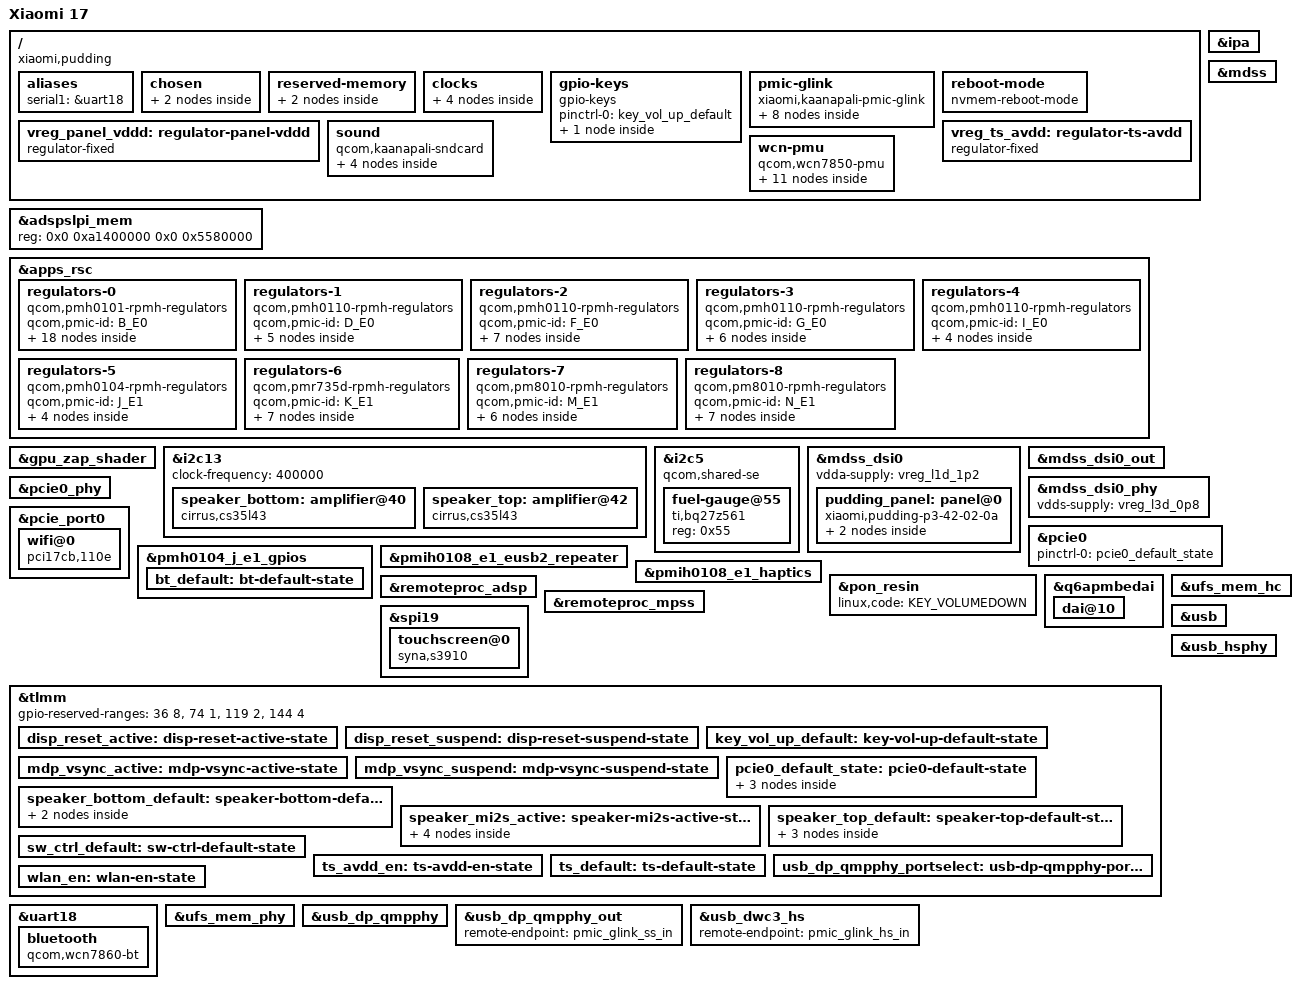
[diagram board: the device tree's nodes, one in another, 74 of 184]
// SPDX-License-Identifier: BSD-3-Clause
/*
 * Xiaomi 17 (pudding), based on kaanapali-mtp.dts
 *
 * Copyright (c) Qualcomm Technologies, Inc. and/or its subsidiaries.
 */

/dts-v1/;

#include <dt-bindings/gpio/gpio.h>
#include <dt-bindings/input/linux-event-codes.h>
#include <dt-bindings/regulator/qcom,rpmh-regulator.h>
/*
 * CPU throttle temperature for kaanapali-cpu-cooling.dtsi: 105 °C is the
 * thermal HAL trip of the cpu-* zones in this phone's stock device tree.
 */
#define KAANAPALI_CPU_PASSIVE_MC 105000
#include "kaanapali.dtsi"

#include "pm8010-kaanapali.dtsi"     /* SPMI1: SID-12/13   */
#include "pmd8028-kaanapali.dtsi"    /* SPMI1: SID-4       */
#include "pmh0101.dtsi"              /* SPMI0: SID-1       */
#include "pmh0104-kaanapali.dtsi"    /* SPMI1: SID-9       */
#include "pmh0110-kaanapali.dtsi"    /* SPMI0: SID-3/5/6/8 */
#include "pmih0108-kaanapali.dtsi"   /* SPMI1: SID-7       */
#include "pmk8850.dtsi"              /* SPMI0: SID-0       */
#include "pmr735d-kaanapali.dtsi"    /* SPMI1: SID-10      */

/ {
	model = "Xiaomi 17";
	compatible = "xiaomi,pudding", "qcom,kaanapali";
	chassis-type = "handset";

	aliases {
		serial1 = &uart18;
	};

	chosen {
		#address-cells = <2>;
		#size-cells = <2>;
		ranges;

		/*
		 * Reboot a minute after a panic or a soft lockup, leaving the
		 * message on screen: the phone has no serial console and should
		 * not need a key reset. The bootloader splash shows the console
		 * until the display driver takes over: keep its clocks and power
		 * domains on. The bootloader always loads init_boot's ramdisk,
		 * and Android's /init may share it: the rescue starts from its
		 * own directory. The GPU is a DRM device of its own, apart from
		 * the display.
		 */
		bootargs = "rdinit=/pudding-rescue/load console=tty0 panic=60 softlockup_panic=1 loglevel=7 log_buf_len=2M bootconfig clk_ignore_unused pd_ignore_unused msm.separate_gpu_kms=1";

		/*
		 * The ABL boots vendor_boot's Canoe tree with the dtbo overlay
		 * for board-id 8 and Xiaomi board 2, whose root model names this
		 * phone. The bootloader ramdisk carries the rescue and boot
		 * userspace.
		 */
		fdt-handoff {
			stock-compatible = "qcom,canoe";
			stock-model = "Qualcomm Technologies, Inc. Pudding based on SM8850";
			keep-initrd;
		};

		/* Bootloader splash, left running by the ABL (1220x2656 DSC panel) */
		framebuffer: framebuffer@fc800000 {
			compatible = "simple-framebuffer";
			reg = <0x0 0xfc800000 0x0 (1220 * 2656 * 4)>;
			width = <1220>;
			height = <2656>;
			stride = <(1220 * 4)>;
			format = "a8r8g8b8";
			/* Keep the splash scanout fed after interconnect sync_state. */
			interconnects = <&mmss_noc MASTER_MDP QCOM_ICC_TAG_ALWAYS
					 &mc_virt SLAVE_EBI1 QCOM_ICC_TAG_ALWAYS>;
			clocks = <&gcc GCC_DISP_HF_AXI_CLK>;
		};
	};

	reserved-memory {
		#address-cells = <2>;
		#size-cells = <2>;
		ranges;

		cont_splash_mem: cont-splash@fc800000 {
			reg = <0x0 0xfc800000 0x0 0x2b00000>;
			no-map;
		};

		/*
		 * Same layout as the stock tree, so Android shows our log in
		 * /sys/fs/pstore. Write-combine (mem-type 0): a cached mapping
		 * would lose the log in the CPU caches on a hard reset.
		 */
		ramoops@ff400000 {
			compatible = "ramoops";
			reg = <0x0 0xff400000 0x0 0x200000>;
			console-size = <0x100000>;
			pmsg-size = <0x100000>;
			mem-type = <0>;
		};
	};

	clocks {
		xo_board: xo-board {
			compatible = "fixed-clock";
			clock-frequency = <76800000>;
			#clock-cells = <0>;
		};

		sleep_clk: sleep-clk {
			compatible = "fixed-clock";
			clock-frequency = <32764>;
			#clock-cells = <0>;
		};

		bi_tcxo_div2: bi-tcxo-div2-clk {
			compatible = "fixed-factor-clock";
			#clock-cells = <0>;

			clocks = <&rpmhcc RPMH_CXO_CLK>;
			clock-mult = <1>;
			clock-div = <2>;
		};

		bi_tcxo_ao_div2: bi-tcxo-ao-div2-clk {
			compatible = "fixed-factor-clock";
			#clock-cells = <0>;

			clocks = <&rpmhcc RPMH_CXO_CLK_A>;
			clock-mult = <1>;
			clock-div = <2>;
		};
	};

	gpio-keys {
		compatible = "gpio-keys";

		pinctrl-0 = <&key_vol_up_default>;
		pinctrl-names = "default";

		key-volume-up {
			label = "Volume Up";
			linux,code = <KEY_VOLUMEUP>;
			gpios = <&tlmm 101 GPIO_ACTIVE_LOW>;
			debounce-interval = <15>;
			linux,can-disable;
			wakeup-source;
		};
	};

	pmic-glink {
		compatible = "xiaomi,kaanapali-pmic-glink", "qcom,kaanapali-pmic-glink",
			     "qcom,pmic-glink";
		#address-cells = <1>;
		#size-cells = <0>;

		connector@0 {
			compatible = "usb-c-connector";
			reg = <0>;

			power-role = "dual";
			data-role = "dual";

			ports {
				#address-cells = <1>;
				#size-cells = <0>;

				port@0 {
					reg = <0>;

					pmic_glink_hs_in: endpoint {
						remote-endpoint = <&usb_dwc3_hs>;
					};
				};

				port@1 {
					reg = <1>;

					pmic_glink_ss_in: endpoint {
						remote-endpoint = <&usb_dp_qmpphy_out>;
					};
				};

				port@2 {
					reg = <2>;

					pmic_glink_sbu: endpoint {
					};
				};
			};
		};
	};

	/* The stock kernel leaves the same values in this cell. */
	reboot-mode {
		compatible = "nvmem-reboot-mode";
		nvmem-cells = <&reboot_reason>;
		nvmem-cell-names = "reboot-mode";
		mode-recovery = <0x01>;
		mode-bootloader = <0x02>;
	};

	/* Panel core supply, a GPIO-switched rail the bootloader leaves on */
	vreg_panel_vddd: regulator-panel-vddd {
		compatible = "regulator-fixed";
		regulator-name = "vreg_panel_vddd";
		regulator-min-microvolt = <1060000>;
		regulator-max-microvolt = <1060000>;
		gpio = <&tlmm 90 GPIO_ACTIVE_HIGH>;
		enable-active-high;
		regulator-boot-on;
	};

	/* Touch analog supply, a GPIO-switched rail with no stock voltage */
	vreg_ts_avdd: regulator-ts-avdd {
		compatible = "regulator-fixed";
		regulator-name = "vreg_ts_avdd";
		gpio = <&tlmm 117 GPIO_ACTIVE_HIGH>;
		enable-active-high;

		pinctrl-0 = <&ts_avdd_en>;
		pinctrl-names = "default";
	};

	sound {
		compatible = "qcom,kaanapali-sndcard", "qcom,sm8450-sndcard";
		model = "Xiaomi-17";

		pinctrl-0 = <&speaker_mi2s_active>;
		pinctrl-names = "default";

		speaker-playback-dai-link {
			link-name = "Speaker Playback";

			codec {
				sound-dai = <&speaker_bottom>, <&speaker_top>;
			};

			cpu {
				sound-dai = <&q6apmbedai PRIMARY_MI2S_RX>;
			};

			platform {
				sound-dai = <&q6apm>;
			};
		};
	};

	/*
	 * The Wi-Fi/BT combo is Qualcomm's "peach" (PCI 17cb:110e), wired as
	 * on the RedMagic 11 Pro: same enable GPIOs, supplies and RF clock
	 * (stock qcom,cnss-peach).
	 */
	wcn-pmu {
		compatible = "qcom,wcn7850-pmu";

		pinctrl-0 = <&bt_default>, <&sw_ctrl_default>, <&wlan_en>;
		pinctrl-names = "default";

		bt-enable-gpios = <&pmh0104_j_e1_gpios 5 GPIO_ACTIVE_HIGH>;
		wlan-enable-gpios = <&tlmm 16 GPIO_ACTIVE_HIGH>;

		vdd-supply = <&vreg_s2j_0p8>;
		vddio-supply = <&vreg_l2g_1p8>;
		vddio1p2-supply = <&vreg_l3g_1p2>;
		vddaon-supply = <&vreg_s7g_0p9>;
		vdddig-supply = <&vreg_s1j_0p8>;
		vddrfa1p2-supply = <&vreg_s7f_1p2>;
		vddrfa1p8-supply = <&vreg_s8f_1p8>;

		clocks = <&rpmhcc RPMH_RF_CLK1>;

		regulators {
			vreg_pmu_rfa_cmn: ldo0 {
				regulator-name = "vreg_pmu_rfa_cmn";
			};

			vreg_pmu_aon_0p59: ldo1 {
				regulator-name = "vreg_pmu_aon_0p59";
			};

			vreg_pmu_wlcx_0p8: ldo2 {
				regulator-name = "vreg_pmu_wlcx_0p8";
			};

			vreg_pmu_wlmx_0p85: ldo3 {
				regulator-name = "vreg_pmu_wlmx_0p85";
			};

			vreg_pmu_btcmx_0p85: ldo4 {
				regulator-name = "vreg_pmu_btcmx_0p85";
			};

			vreg_pmu_rfa_0p8: ldo5 {
				regulator-name = "vreg_pmu_rfa_0p8";
			};

			vreg_pmu_rfa_1p2: ldo6 {
				regulator-name = "vreg_pmu_rfa_1p2";
			};

			vreg_pmu_rfa_1p8: ldo7 {
				regulator-name = "vreg_pmu_rfa_1p8";
			};

			vreg_pmu_pcie_0p9: ldo8 {
				regulator-name = "vreg_pmu_pcie_0p9";
			};

			vreg_pmu_pcie_1p8: ldo9 {
				regulator-name = "vreg_pmu_pcie_1p8";
			};
		};
	};
};

/* Xiaomi's ADSP firmware spans 85.5 MiB, as the stock carve-out does */
&adspslpi_mem {
	reg = <0x0 0xa1400000 0x0 0x5580000>;
};

&apps_rsc {
	regulators-0 {
		compatible = "qcom,pmh0101-rpmh-regulators";
		qcom,pmic-id = "B_E0";

		/* Stock 3.4 V, between two of the BOB's 32 mV steps. */
		vreg_bob1: bob1 {
			regulator-name = "vreg_bob1";
			regulator-min-microvolt = <3416000>;
			regulator-max-microvolt = <3416000>;
			regulator-initial-mode = <RPMH_REGULATOR_MODE_HPM>;
		};

		vreg_bob2: bob2 {
			regulator-name = "vreg_bob2";
			regulator-min-microvolt = <2704000>;
			regulator-max-microvolt = <3296000>;
			regulator-initial-mode = <RPMH_REGULATOR_MODE_HPM>;
		};

		vreg_l1b_1p8: ldo1 {
			regulator-name = "vreg_l1b_1p8";
			regulator-min-microvolt = <1800000>;
			regulator-max-microvolt = <1800000>;
			regulator-initial-mode = <RPMH_REGULATOR_MODE_AUTO>;
			regulator-allow-set-load;
			regulator-allowed-modes = <RPMH_REGULATOR_MODE_LPM
						   RPMH_REGULATOR_MODE_AUTO>;
		};

		vreg_l2b_3p3: ldo2 {
			regulator-name = "vreg_l2b_3p3";
			regulator-min-microvolt = <3304000>;
			regulator-max-microvolt = <3304000>;
			regulator-initial-mode = <RPMH_REGULATOR_MODE_AUTO>;
			regulator-allow-set-load;
			regulator-allowed-modes = <RPMH_REGULATOR_MODE_LPM
						   RPMH_REGULATOR_MODE_AUTO>;
		};

		vreg_l4b_1p8: ldo4 {
			regulator-name = "vreg_l4b_1p8";
			regulator-min-microvolt = <1800000>;
			regulator-max-microvolt = <1800000>;
			regulator-initial-mode = <RPMH_REGULATOR_MODE_AUTO>;
			regulator-allow-set-load;
			regulator-allowed-modes = <RPMH_REGULATOR_MODE_LPM
						   RPMH_REGULATOR_MODE_AUTO>;
		};

		vreg_l5b_3p1: ldo5 {
			regulator-name = "vreg_l5b_3p1";
			regulator-min-microvolt = <3100000>;
			regulator-max-microvolt = <3148000>;
			regulator-initial-mode = <RPMH_REGULATOR_MODE_AUTO>;
			regulator-allow-set-load;
			regulator-allowed-modes = <RPMH_REGULATOR_MODE_LPM
						   RPMH_REGULATOR_MODE_AUTO>;
		};

		vreg_l6b_1p8: ldo6 {
			regulator-name = "vreg_l6b_1p8";
			regulator-min-microvolt = <1800000>;
			regulator-max-microvolt = <3008000>;
			regulator-initial-mode = <RPMH_REGULATOR_MODE_AUTO>;
			regulator-allow-set-load;
			regulator-allowed-modes = <RPMH_REGULATOR_MODE_LPM
						   RPMH_REGULATOR_MODE_AUTO>;
		};

		vreg_l7b_1p8: ldo7 {
			regulator-name = "vreg_l7b_1p8";
			regulator-min-microvolt = <1800000>;
			regulator-max-microvolt = <3008000>;
			regulator-initial-mode = <RPMH_REGULATOR_MODE_AUTO>;
			regulator-allow-set-load;
			regulator-allowed-modes = <RPMH_REGULATOR_MODE_LPM
						   RPMH_REGULATOR_MODE_AUTO>;
		};

		vreg_l8b_1p8: ldo8 {
			regulator-name = "vreg_l8b_1p8";
			regulator-min-microvolt = <1800000>;
			regulator-max-microvolt = <3008000>;
			regulator-initial-mode = <RPMH_REGULATOR_MODE_AUTO>;
			regulator-allow-set-load;
			regulator-allowed-modes = <RPMH_REGULATOR_MODE_LPM
						   RPMH_REGULATOR_MODE_AUTO>;
		};

		/* Stock 3.3 V, above this LDO's top step. */
		vreg_l9b_3p3: ldo9 {
			regulator-name = "vreg_l9b_3p3";
			regulator-min-microvolt = <3296000>;
			regulator-max-microvolt = <3296000>;
			regulator-initial-mode = <RPMH_REGULATOR_MODE_HPM>;
			regulator-allow-set-load;
			regulator-allowed-modes = <RPMH_REGULATOR_MODE_LPM
						   RPMH_REGULATOR_MODE_HPM>;
		};

		vreg_l10b_1p8: ldo10 {
			regulator-name = "vreg_l10b_1p8";
			regulator-min-microvolt = <1800000>;
			regulator-max-microvolt = <1800000>;
			regulator-initial-mode = <RPMH_REGULATOR_MODE_AUTO>;
			regulator-allow-set-load;
			regulator-allowed-modes = <RPMH_REGULATOR_MODE_LPM
						   RPMH_REGULATOR_MODE_AUTO>;
		};

		vreg_l11b_1p0: ldo11 {
			regulator-name = "vreg_l11b_1p0";
			regulator-min-microvolt = <1000000>;
			regulator-max-microvolt = <1292000>;
			regulator-initial-mode = <RPMH_REGULATOR_MODE_AUTO>;
			regulator-allow-set-load;
			regulator-allowed-modes = <RPMH_REGULATOR_MODE_LPM
						   RPMH_REGULATOR_MODE_AUTO>;
		};

		vreg_l12b_1p8: ldo12 {
			regulator-name = "vreg_l12b_1p8";
			regulator-min-microvolt = <1650000>;
			regulator-max-microvolt = <1800000>;
			regulator-initial-mode = <RPMH_REGULATOR_MODE_AUTO>;
			regulator-allow-set-load;
			regulator-allowed-modes = <RPMH_REGULATOR_MODE_LPM
						   RPMH_REGULATOR_MODE_AUTO>;
		};

		vreg_l13b_3p0: ldo13 {
			regulator-name = "vreg_l13b_3p0";
			regulator-min-microvolt = <3000000>;
			regulator-max-microvolt = <3000000>;
			regulator-initial-mode = <RPMH_REGULATOR_MODE_AUTO>;
			regulator-allow-set-load;
			regulator-allowed-modes = <RPMH_REGULATOR_MODE_LPM
						   RPMH_REGULATOR_MODE_AUTO>;
		};

		/* Panel vci, at the stock panel's 3.0 V */
		vreg_l14b_3p0: ldo14 {
			regulator-name = "vreg_l14b_3p0";
			regulator-min-microvolt = <3000000>;
			regulator-max-microvolt = <3000000>;
			regulator-initial-mode = <RPMH_REGULATOR_MODE_AUTO>;
			regulator-allow-set-load;
			regulator-allowed-modes = <RPMH_REGULATOR_MODE_LPM
						   RPMH_REGULATOR_MODE_AUTO>;
		};

		vreg_l15b_1p8: ldo15 {
			regulator-name = "vreg_l15b_1p8";
			regulator-min-microvolt = <1800000>;
			regulator-max-microvolt = <1800000>;
			regulator-initial-mode = <RPMH_REGULATOR_MODE_AUTO>;
			regulator-allow-set-load;
			regulator-allowed-modes = <RPMH_REGULATOR_MODE_LPM
						   RPMH_REGULATOR_MODE_AUTO>;
		};

		vreg_l17b_2p5: ldo17 {
			regulator-name = "vreg_l17b_2p5";
			regulator-min-microvolt = <2504000>;
			regulator-max-microvolt = <2504000>;
			regulator-initial-mode = <RPMH_REGULATOR_MODE_HPM>;
			regulator-allow-set-load;
			regulator-allowed-modes = <RPMH_REGULATOR_MODE_LPM
						   RPMH_REGULATOR_MODE_HPM>;
		};

		vreg_l18b_1p0: ldo18 {
			regulator-name = "vreg_l18b_1p0";
			regulator-min-microvolt = <1000000>;
			regulator-max-microvolt = <1000000>;
			regulator-initial-mode = <RPMH_REGULATOR_MODE_AUTO>;
			regulator-allow-set-load;
			regulator-allowed-modes = <RPMH_REGULATOR_MODE_LPM
						   RPMH_REGULATOR_MODE_AUTO>;
		};
	};

	regulators-1 {
		compatible = "qcom,pmh0110-rpmh-regulators";
		qcom,pmic-id = "D_E0";

		vreg_s10d_1p0: smps10 {
			regulator-name = "vreg_s10d_1p0";
			regulator-min-microvolt = <1000000>;
			regulator-max-microvolt = <1100000>;
			regulator-initial-mode = <RPMH_REGULATOR_MODE_HPM>;
		};

		vreg_l1d_1p2: ldo1 {
			regulator-name = "vreg_l1d_1p2";
			regulator-min-microvolt = <1200000>;
			regulator-max-microvolt = <1256000>;
			regulator-initial-mode = <RPMH_REGULATOR_MODE_AUTO>;
			regulator-allow-set-load;
			regulator-allowed-modes = <RPMH_REGULATOR_MODE_LPM
						   RPMH_REGULATOR_MODE_AUTO>;
		};

		vreg_l2d_0p9: ldo2 {
			regulator-name = "vreg_l2d_0p9";
			regulator-min-microvolt = <912000>;
			regulator-max-microvolt = <958000>;
			regulator-initial-mode = <RPMH_REGULATOR_MODE_AUTO>;
			regulator-allow-set-load;
			regulator-allowed-modes = <RPMH_REGULATOR_MODE_LPM
						   RPMH_REGULATOR_MODE_AUTO>;
		};

		vreg_l3d_0p8: ldo3 {
			regulator-name = "vreg_l3d_0p8";
			regulator-min-microvolt = <880000>;
			regulator-max-microvolt = <880000>;
			regulator-initial-mode = <RPMH_REGULATOR_MODE_AUTO>;
			regulator-allow-set-load;
			regulator-allowed-modes = <RPMH_REGULATOR_MODE_LPM
						   RPMH_REGULATOR_MODE_AUTO>;
		};

		vreg_l4d_1p2: ldo4 {
			regulator-name = "vreg_l4d_1p2";
			regulator-min-microvolt = <1200000>;
			regulator-max-microvolt = <1200000>;
			regulator-initial-mode = <RPMH_REGULATOR_MODE_AUTO>;
			regulator-allow-set-load;
			regulator-allowed-modes = <RPMH_REGULATOR_MODE_LPM
						   RPMH_REGULATOR_MODE_AUTO>;
		};
	};

	regulators-2 {
		compatible = "qcom,pmh0110-rpmh-regulators";
		qcom,pmic-id = "F_E0";

		vreg_s6f_0p5: smps6 {
			regulator-name = "vreg_s6f_0p5";
			regulator-min-microvolt = <300000>;
			regulator-max-microvolt = <570000>;
			regulator-initial-mode = <RPMH_REGULATOR_MODE_HPM>;
		};

		/*
		 * S7F/S8F feed the Wi-Fi/BT chip's RF (and PCIe) rails. As for
		 * S1J/S2J, nothing sets their voltage: use downstream cnss2's
		 * vdd-wlan-rfa2/rfa1 floors, 1.328 V and 1.876 V.
		 */
		vreg_s7f_1p2: smps7 {
			regulator-name = "vreg_s7f_1p2";
			regulator-min-microvolt = <1328000>;
			regulator-max-microvolt = <1372000>;
			regulator-initial-mode = <RPMH_REGULATOR_MODE_HPM>;
		};

		vreg_s8f_1p8: smps8 {
			regulator-name = "vreg_s8f_1p8";
			regulator-min-microvolt = <1876000>;
			regulator-max-microvolt = <2000000>;
			regulator-initial-mode = <RPMH_REGULATOR_MODE_HPM>;
		};

		vreg_l1f_1p2: ldo1 {
			regulator-name = "vreg_l1f_1p2";
			regulator-min-microvolt = <1200000>;
			regulator-max-microvolt = <1200000>;
			regulator-initial-mode = <RPMH_REGULATOR_MODE_AUTO>;
			regulator-allow-set-load;
			regulator-allowed-modes = <RPMH_REGULATOR_MODE_LPM
						   RPMH_REGULATOR_MODE_AUTO>;
		};

		vreg_l2f_1p2: ldo2 {
			regulator-name = "vreg_l2f_1p2";
			regulator-min-microvolt = <1200000>;
			regulator-max-microvolt = <1200000>;
			regulator-initial-mode = <RPMH_REGULATOR_MODE_AUTO>;
			regulator-allow-set-load;
			regulator-allowed-modes = <RPMH_REGULATOR_MODE_LPM
						   RPMH_REGULATOR_MODE_AUTO>;
		};

		vreg_l3f_0p8: ldo3 {
			regulator-name = "vreg_l3f_0p8";
			regulator-min-microvolt = <880000>;
			regulator-max-microvolt = <936000>;
			regulator-initial-mode = <RPMH_REGULATOR_MODE_AUTO>;
			regulator-allow-set-load;
			regulator-allowed-modes = <RPMH_REGULATOR_MODE_LPM
						   RPMH_REGULATOR_MODE_AUTO>;
		};

		vreg_l4f_0p8: ldo4 {
			regulator-name = "vreg_l4f_0p8";
			regulator-min-microvolt = <880000>;
			regulator-max-microvolt = <912000>;
			regulator-initial-mode = <RPMH_REGULATOR_MODE_AUTO>;
			regulator-allow-set-load;
			regulator-allowed-modes = <RPMH_REGULATOR_MODE_LPM
						   RPMH_REGULATOR_MODE_AUTO>;
		};
	};

	regulators-3 {
		compatible = "qcom,pmh0110-rpmh-regulators";
		qcom,pmic-id = "G_E0";

		vreg_s7g_0p9: smps7 {
			regulator-name = "vreg_s7g_0p9";
			regulator-min-microvolt = <880000>;
			regulator-max-microvolt = <1100000>;
			regulator-initial-mode = <RPMH_REGULATOR_MODE_HPM>;
		};

		vreg_s9g_1p0: smps9 {
			regulator-name = "vreg_s9g_1p0";
			regulator-min-microvolt = <1000000>;
			regulator-max-microvolt = <1100000>;
			regulator-initial-mode = <RPMH_REGULATOR_MODE_HPM>;
		};

		vreg_l1g_1p2: ldo1 {
			regulator-name = "vreg_l1g_1p2";
			regulator-min-microvolt = <1200000>;
			regulator-max-microvolt = <1200000>;
			regulator-initial-mode = <RPMH_REGULATOR_MODE_AUTO>;
			regulator-allow-set-load;
			regulator-allowed-modes = <RPMH_REGULATOR_MODE_LPM
						   RPMH_REGULATOR_MODE_AUTO>;
		};

		vreg_l2g_1p8: ldo2 {
			regulator-name = "vreg_l2g_1p8";
			regulator-min-microvolt = <1800000>;
			regulator-max-microvolt = <1800000>;
			regulator-initial-mode = <RPMH_REGULATOR_MODE_AUTO>;
			regulator-allow-set-load;
			regulator-allowed-modes = <RPMH_REGULATOR_MODE_LPM
						   RPMH_REGULATOR_MODE_AUTO>;
		};

		vreg_l3g_1p2: ldo3 {
			regulator-name = "vreg_l3g_1p2";
			regulator-min-microvolt = <1200000>;
			regulator-max-microvolt = <1200000>;
			regulator-initial-mode = <RPMH_REGULATOR_MODE_AUTO>;
			regulator-allow-set-load;
			regulator-allowed-modes = <RPMH_REGULATOR_MODE_LPM
						   RPMH_REGULATOR_MODE_AUTO>;
		};

		vreg_l4g_0p9: ldo4 {
			regulator-name = "vreg_l4g_0p9";
			regulator-min-microvolt = <912000>;
			regulator-max-microvolt = <912000>;
			regulator-initial-mode = <RPMH_REGULATOR_MODE_AUTO>;
			regulator-allow-set-load;
			regulator-allowed-modes = <RPMH_REGULATOR_MODE_LPM
						   RPMH_REGULATOR_MODE_AUTO>;
		};
	};

	regulators-4 {
		compatible = "qcom,pmh0110-rpmh-regulators";
		qcom,pmic-id = "I_E0";

		vreg_s7i_0p9: smps7 {
			regulator-name = "vreg_s7i_0p9";
			regulator-min-microvolt = <900000>;
			regulator-max-microvolt = <972000>;
			regulator-initial-mode = <RPMH_REGULATOR_MODE_HPM>;
		};

		vreg_l2i_1p2: ldo2 {
			regulator-name = "vreg_l2i_1p2";
			regulator-min-microvolt = <1200000>;
			regulator-max-microvolt = <1200000>;
			regulator-initial-mode = <RPMH_REGULATOR_MODE_AUTO>;
			regulator-allow-set-load;
			regulator-allowed-modes = <RPMH_REGULATOR_MODE_LPM
						   RPMH_REGULATOR_MODE_AUTO>;
		};

		vreg_l3i_0p8: ldo3 {
			regulator-name = "vreg_l3i_0p8";
			regulator-min-microvolt = <880000>;
			regulator-max-microvolt = <920000>;
			regulator-initial-mode = <RPMH_REGULATOR_MODE_AUTO>;
			regulator-allow-set-load;
			regulator-allowed-modes = <RPMH_REGULATOR_MODE_LPM
						   RPMH_REGULATOR_MODE_AUTO>;
		};

		vreg_l4i_1p8: ldo4 {
			regulator-name = "vreg_l4i_1p8";
			regulator-min-microvolt = <1800000>;
			regulator-max-microvolt = <1800000>;
			regulator-initial-mode = <RPMH_REGULATOR_MODE_HPM>;
		};
	};

	regulators-5 {
		compatible = "qcom,pmh0104-rpmh-regulators";
		qcom,pmic-id = "J_E1";

		/*
		 * S1J/S2J are the Wi-Fi/BT chip's CX and digital rails. Nothing
		 * sets their voltage, so the floor is what gets voted: keep it at
		 * downstream cnss2's 0.892 V.
		 */
		vreg_s1j_0p8: smps1 {
			regulator-name = "vreg_s1j_0p8";
			regulator-min-microvolt = <892000>;
			regulator-max-microvolt = <1000000>;
			regulator-initial-mode = <RPMH_REGULATOR_MODE_HPM>;
		};

		vreg_s2j_0p8: smps2 {
			regulator-name = "vreg_s2j_0p8";
			regulator-min-microvolt = <892000>;
			regulator-max-microvolt = <1000000>;
			regulator-initial-mode = <RPMH_REGULATOR_MODE_HPM>;
		};

		vreg_s3j_1p2: smps3 {
			regulator-name = "vreg_s3j_1p2";
			regulator-min-microvolt = <1200000>;
			regulator-max-microvolt = <1300000>;
			regulator-initial-mode = <RPMH_REGULATOR_MODE_HPM>;
		};

		vreg_s4j_0p7: smps4 {
			regulator-name = "vreg_s4j_0p7";
			regulator-min-microvolt = <300000>;
			regulator-max-microvolt = <1000000>;
			regulator-initial-mode = <RPMH_REGULATOR_MODE_HPM>;
		};
	};

	regulators-6 {
		compatible = "qcom,pmr735d-rpmh-regulators";
		qcom,pmic-id = "K_E1";

		vreg_l1k_0p8: ldo1 {
			regulator-name = "vreg_l1k_0p8";
			regulator-min-microvolt = <300000>;
			regulator-max-microvolt = <1100000>;
			regulator-initial-mode = <RPMH_REGULATOR_MODE_HPM>;
			regulator-allow-set-load;
			regulator-allowed-modes = <RPMH_REGULATOR_MODE_LPM
						   RPMH_REGULATOR_MODE_HPM>;
		};

		vreg_l2k_0p7: ldo2 {
			regulator-name = "vreg_l2k_0p7";
			regulator-min-microvolt = <700000>;
			regulator-max-microvolt = <1000000>;
			regulator-initial-mode = <RPMH_REGULATOR_MODE_HPM>;
			regulator-allow-set-load;
			regulator-allowed-modes = <RPMH_REGULATOR_MODE_LPM
						   RPMH_REGULATOR_MODE_HPM>;
		};

		/* Wi-Fi/BT antenna sharing (stock vdd-wlan-ant-share) */
		vreg_l3k_1p2: ldo3 {
			regulator-name = "vreg_l3k_1p2";
			regulator-min-microvolt = <1200000>;
			regulator-max-microvolt = <1200000>;
			regulator-initial-mode = <RPMH_REGULATOR_MODE_HPM>;
			regulator-always-on;
			regulator-allow-set-load;
			regulator-allowed-modes = <RPMH_REGULATOR_MODE_LPM
						   RPMH_REGULATOR_MODE_HPM>;
		};

		vreg_l4k_1p0: ldo4 {
			regulator-name = "vreg_l4k_1p0";
			regulator-min-microvolt = <1000000>;
			regulator-max-microvolt = <1200000>;
			regulator-initial-mode = <RPMH_REGULATOR_MODE_HPM>;
			regulator-allow-set-load;
			regulator-allowed-modes = <RPMH_REGULATOR_MODE_LPM
						   RPMH_REGULATOR_MODE_HPM>;
		};

		vreg_l5k_0p7: ldo5 {
			regulator-name = "vreg_l5k_0p7";
			regulator-min-microvolt = <700000>;
			regulator-max-microvolt = <1000000>;
			regulator-initial-mode = <RPMH_REGULATOR_MODE_HPM>;
			regulator-allow-set-load;
			regulator-allowed-modes = <RPMH_REGULATOR_MODE_LPM
						   RPMH_REGULATOR_MODE_HPM>;
		};

		vreg_l6k_1p7: ldo6 {
			regulator-name = "vreg_l6k_1p7";
			regulator-min-microvolt = <1700000>;
			regulator-max-microvolt = <2000000>;
			regulator-initial-mode = <RPMH_REGULATOR_MODE_HPM>;
			regulator-allow-set-load;
			regulator-allowed-modes = <RPMH_REGULATOR_MODE_LPM
						   RPMH_REGULATOR_MODE_HPM>;
		};

		vreg_l7k_0p7: ldo7 {
			regulator-name = "vreg_l7k_0p7";
			regulator-min-microvolt = <700000>;
			regulator-max-microvolt = <848000>;
			regulator-initial-mode = <RPMH_REGULATOR_MODE_HPM>;
			regulator-allow-set-load;
			regulator-allowed-modes = <RPMH_REGULATOR_MODE_LPM
						   RPMH_REGULATOR_MODE_HPM>;
		};
	};

	regulators-7 {
		compatible = "qcom,pm8010-rpmh-regulators";
		qcom,pmic-id = "M_E1";

		vreg_l1m_1p0: ldo1 {
			regulator-name = "vreg_l1m_1p0";
			regulator-min-microvolt = <1000000>;
			regulator-max-microvolt = <1100000>;
			regulator-initial-mode = <RPMH_REGULATOR_MODE_HPM>;
			regulator-allow-set-load;
			regulator-allowed-modes = <RPMH_REGULATOR_MODE_LPM
						   RPMH_REGULATOR_MODE_HPM>;
		};

		vreg_l2m_1p0: ldo2 {
			regulator-name = "vreg_l2m_1p0";
			regulator-min-microvolt = <1096000>;
			regulator-max-microvolt = <1104000>;
			regulator-initial-mode = <RPMH_REGULATOR_MODE_HPM>;
			regulator-allow-set-load;
			regulator-allowed-modes = <RPMH_REGULATOR_MODE_LPM
						   RPMH_REGULATOR_MODE_HPM>;
		};

		vreg_l3m_2p8: ldo3 {
			regulator-name = "vreg_l3m_2p8";
			regulator-min-microvolt = <2800000>;
			regulator-max-microvolt = <2900000>;
			regulator-initial-mode = <RPMH_REGULATOR_MODE_HPM>;
		};

		vreg_l4m_1p8: ldo4 {
			regulator-name = "vreg_l4m_1p8";
			regulator-min-microvolt = <1800000>;
			regulator-max-microvolt = <1800000>;
			regulator-initial-mode = <RPMH_REGULATOR_MODE_HPM>;
		};

		vreg_l6m_2p8: ldo6 {
			regulator-name = "vreg_l6m_2p8";
			regulator-min-microvolt = <2800000>;
			regulator-max-microvolt = <2800000>;
			regulator-initial-mode = <RPMH_REGULATOR_MODE_HPM>;
		};

		vreg_l7m_2p8: ldo7 {
			regulator-name = "vreg_l7m_2p8";
			regulator-min-microvolt = <2800000>;
			regulator-max-microvolt = <2800000>;
			regulator-initial-mode = <RPMH_REGULATOR_MODE_HPM>;
		};
	};

	regulators-8 {
		compatible = "qcom,pm8010-rpmh-regulators";
		qcom,pmic-id = "N_E1";

		vreg_l1n_1p1: ldo1 {
			regulator-name = "vreg_l1n_1p1";
			regulator-min-microvolt = <1096000>;
			regulator-max-microvolt = <1104000>;
			regulator-initial-mode = <RPMH_REGULATOR_MODE_HPM>;
			regulator-allow-set-load;
			regulator-allowed-modes = <RPMH_REGULATOR_MODE_LPM
						   RPMH_REGULATOR_MODE_HPM>;
		};

		vreg_l2n_1p2: ldo2 {
			regulator-name = "vreg_l2n_1p2";
			regulator-min-microvolt = <1200000>;
			regulator-max-microvolt = <1200000>;
			regulator-initial-mode = <RPMH_REGULATOR_MODE_HPM>;
			regulator-allow-set-load;
			regulator-allowed-modes = <RPMH_REGULATOR_MODE_LPM
						   RPMH_REGULATOR_MODE_HPM>;
		};

		vreg_l3n_1p8: ldo3 {
			regulator-name = "vreg_l3n_1p8";
			regulator-min-microvolt = <1800000>;
			regulator-max-microvolt = <1800000>;
			regulator-initial-mode = <RPMH_REGULATOR_MODE_HPM>;
		};

		vreg_l4n_1p8: ldo4 {
			regulator-name = "vreg_l4n_1p8";
			regulator-min-microvolt = <1800000>;
			regulator-max-microvolt = <1800000>;
			regulator-initial-mode = <RPMH_REGULATOR_MODE_HPM>;
		};

		vreg_l5n_2p8: ldo5 {
			regulator-name = "vreg_l5n_2p8";
			regulator-min-microvolt = <2800000>;
			regulator-max-microvolt = <2800000>;
			regulator-initial-mode = <RPMH_REGULATOR_MODE_HPM>;
		};

		vreg_l6n_2p8: ldo6 {
			regulator-name = "vreg_l6n_2p8";
			regulator-min-microvolt = <2800000>;
			regulator-max-microvolt = <2800000>;
			regulator-initial-mode = <RPMH_REGULATOR_MODE_HPM>;
		};

		vreg_l7n_3p3: ldo7 {
			regulator-name = "vreg_l7n_3p3";
			regulator-min-microvolt = <3304000>;
			regulator-max-microvolt = <3304000>;
			regulator-initial-mode = <RPMH_REGULATOR_MODE_HPM>;
		};
	};
};

&gpu_zap_shader {
	firmware-name = "qcom/kaanapali/xiaomi/pudding/gen80200_zap.mbn";
};

&i2c13 {
	clock-frequency = <400000>;

	status = "okay";

	/* Bottom speaker; stock settings */
	speaker_bottom: amplifier@40 {
		compatible = "cirrus,cs35l43";
		reg = <0x40>;

		interrupts-extended = <&tlmm 11 IRQ_TYPE_LEVEL_LOW>;
		reset-gpios = <&tlmm 10 GPIO_ACTIVE_HIGH>;

		pinctrl-0 = <&speaker_bottom_default>;
		pinctrl-names = "default";

		#sound-dai-cells = <0>;
		sound-name-prefix = "B";

		cirrus,asp-sdout-hiz = <3>;
		cirrus,bst-ipk-ma = <4000>;
		cirrus,firmware-uid = "xiaomi-pudding";
		cirrus,gpio2-src-sel = <4>;
		cirrus,low-pwr-mode-standby;
		cirrus,vpbr-atk-rate = <0>;
		cirrus,vpbr-atk-vol = <5>;
		cirrus,vpbr-enable;
		cirrus,vpbr-max-att = <6>;
		cirrus,vpbr-rel-rate = <0>;
		cirrus,vpbr-thld = <4>;
		cirrus,vpbr-wait = <0>;
	};

	/* Top speaker; stock settings */
	speaker_top: amplifier@42 {
		compatible = "cirrus,cs35l43";
		reg = <0x42>;

		interrupts-extended = <&tlmm 47 IRQ_TYPE_LEVEL_LOW>;
		reset-gpios = <&tlmm 54 GPIO_ACTIVE_HIGH>;

		pinctrl-0 = <&speaker_top_default>;
		pinctrl-names = "default";

		#sound-dai-cells = <0>;
		sound-name-prefix = "T";

		cirrus,asp-sdout-hiz = <3>;
		cirrus,bst-ipk-ma = <4000>;
		cirrus,firmware-uid = "xiaomi-pudding";
		cirrus,gpio2-src-sel = <4>;
		cirrus,low-pwr-mode-standby;
		cirrus,vpbr-atk-rate = <0>;
		cirrus,vpbr-atk-vol = <5>;
		cirrus,vpbr-enable;
		cirrus,vpbr-max-att = <6>;
		cirrus,vpbr-rel-rate = <0>;
		cirrus,vpbr-thld = <4>;
		cirrus,vpbr-wait = <0>;
	};
};

&i2c5 {
	/*
	 * The SoCCP reads the gauge on this bus too. Also here: the sc8585
	 * charge pump at 0x6e and an hl7603 at 0x77.
	 */
	qcom,shared-se;

	status = "okay";

	fuel-gauge@55 {
		compatible = "ti,bq27z561";
		reg = <0x55>;
	};
};

&ipa {
	firmware-name = "qcom/kaanapali/xiaomi/pudding/ipa_fws.mbn";

	status = "okay";
};

&mdss {
	status = "okay";
};

&mdss_dsi0 {
	vdda-supply = <&vreg_l1d_1p2>;

	status = "okay";

	pudding_panel: panel@0 {
		compatible = "xiaomi,pudding-p3-42-02-0a";
		reg = <0>;

		pinctrl-0 = <&disp_reset_active &mdp_vsync_active>;
		pinctrl-1 = <&disp_reset_suspend &mdp_vsync_suspend>;
		pinctrl-names = "default", "sleep";

		vddio-supply = <&vreg_l12b_1p8>;
		vddd-supply = <&vreg_panel_vddd>;
		vci-supply = <&vreg_l14b_3p0>;

		reset-gpios = <&tlmm 98 GPIO_ACTIVE_LOW>;
		/* The OLED power chip, "pmic reset" in the stock tree */
		pmic-reset-gpios = <&tlmm 171 GPIO_ACTIVE_LOW>;

		port {
			panel0_in: endpoint {
				remote-endpoint = <&mdss_dsi0_out>;
			};
		};
	};
};

&mdss_dsi0_out {
	remote-endpoint = <&panel0_in>;
	data-lanes = <0 1 2 3>;
};

&mdss_dsi0_phy {
	vdds-supply = <&vreg_l3d_0p8>;

	status = "okay";
};

&pcie0 {
	pinctrl-0 = <&pcie0_default_state>;
	pinctrl-names = "default";

	status = "okay";
};

&pcie0_phy {
	vdda-phy-supply = <&vreg_l3i_0p8>;
	vdda-pll-supply = <&vreg_l1d_1p2>;

	status = "okay";
};

&pcie_port0 {
	wake-gpios = <&tlmm 104 GPIO_ACTIVE_LOW>;
	reset-gpios = <&tlmm 102 GPIO_ACTIVE_LOW>;

	wifi@0 {
		compatible = "pci17cb,110e";
		reg = <0x10000 0x0 0x0 0x0 0x0>;

		vddrfacmn-supply = <&vreg_pmu_rfa_cmn>;
		vddaon-supply = <&vreg_pmu_aon_0p59>;
		vddwlcx-supply = <&vreg_pmu_wlcx_0p8>;
		vddwlmx-supply = <&vreg_pmu_wlmx_0p85>;
		vddrfa0p8-supply = <&vreg_pmu_rfa_0p8>;
		vddrfa1p2-supply = <&vreg_pmu_rfa_1p2>;
		vddrfa1p8-supply = <&vreg_pmu_rfa_1p8>;
		vddpcie0p9-supply = <&vreg_pmu_pcie_0p9>;
		vddpcie1p8-supply = <&vreg_pmu_pcie_1p8>;
	};
};

&pmh0104_j_e1_gpios {
	bt_default: bt-default-state {
		pins = "gpio5";
		function = "normal";
		input-disable;
		output-enable;
		output-low;
		bias-disable;
		power-source = <1>;
	};
};

&pmih0108_e1_eusb2_repeater {
	vdd18-supply = <&vreg_l15b_1p8>;
	vdd3-supply = <&vreg_l5b_3p1>;
};

&pmih0108_e1_haptics {
	/* Stock qcom,hv-haptics: vmax 1250 mV, LRA period 5714 us */
	qcom,vmax-microvolt = <1250000>;
	qcom,lra-period-us = <5715>;

	status = "okay";
};

&pon_resin {
	linux,code = <KEY_VOLUMEDOWN>;

	status = "okay";
};

&q6apmbedai {
	#address-cells = <1>;
	#size-cells = <0>;

	dai@10 {
		reg = <PRIMARY_MI2S_RX>;
		clocks = <&q6prmcc LPASS_CLK_ID_PRI_MI2S_IBIT LPASS_CLK_ATTRIBUTE_COUPLE_NO>;
		clock-names = "bclk";
	};
};

&remoteproc_adsp {
	firmware-name = "qcom/kaanapali/xiaomi/pudding/adsp.mbn",
			"qcom/kaanapali/xiaomi/pudding/adsp_dtb.mbn";

	status = "okay";
};

&remoteproc_mpss {
	firmware-name = "qcom/kaanapali/xiaomi/pudding/modem.mbn",
			"qcom/kaanapali/xiaomi/pudding/modem_dtb.mbn";

	status = "okay";
};

&spi19 {
	status = "okay";

	/* Synaptics TouchComm; the stock node also names a Novatek part */
	touchscreen@0 {
		compatible = "syna,s3910";
		reg = <0>;
		spi-max-frequency = <15000000>;
		panel = <&pudding_panel>;

		interrupts-extended = <&tlmm 158 IRQ_TYPE_LEVEL_LOW>;
		reset-gpios = <&tlmm 66 GPIO_ACTIVE_LOW>;

		vdd-supply = <&vreg_l4i_1p8>;
		avdd-supply = <&vreg_ts_avdd>;

		/* 270 frames a second; the firmware starts at 135 */
		syna,report-rate = <3>;

		pinctrl-0 = <&ts_default>;
		pinctrl-names = "default";
	};
};

&tlmm {
	/* From qcom,gpios-reserved in the stock device tree */
	gpio-reserved-ranges = <36 8>, <74 1>, <119 2>, <144 4>;

	disp_reset_active: disp-reset-active-state {
		pins = "gpio98";
		function = "gpio";
		drive-strength = <8>;
		bias-disable;
	};

	disp_reset_suspend: disp-reset-suspend-state {
		pins = "gpio98";
		function = "gpio";
		drive-strength = <2>;
		bias-pull-down;
	};

	key_vol_up_default: key-vol-up-default-state {
		pins = "gpio101";
		function = "gpio";
		output-disable;
		bias-pull-up;
	};

	mdp_vsync_active: mdp-vsync-active-state {
		pins = "gpio86";
		function = "mdp_vsync";
		drive-strength = <2>;
		bias-pull-down;
	};

	mdp_vsync_suspend: mdp-vsync-suspend-state {
		pins = "gpio86";
		function = "mdp_vsync";
		drive-strength = <2>;
		bias-pull-down;
	};

	pcie0_default_state: pcie0-default-state {
		perst-n-pins {
			pins = "gpio102";
			function = "gpio";
			drive-strength = <2>;
			bias-disable;
		};

		clkreq-n-pins {
			pins = "gpio103";
			function = "pcie0_clk_req_n";
			drive-strength = <2>;
			bias-pull-up;
		};

		wake-n-pins {
			pins = "gpio104";
			function = "gpio";
			drive-strength = <2>;
			bias-pull-up;
		};
	};

	speaker_bottom_default: speaker-bottom-default-state {
		reset-pins {
			pins = "gpio10";
			function = "gpio";
			drive-strength = <16>;
			bias-disable;
		};

		irq-pins {
			pins = "gpio11";
			function = "gpio";
			drive-strength = <2>;
			bias-pull-up;
		};
	};

	speaker_mi2s_active: speaker-mi2s-active-state {
		sck-pins {
			pins = "gpio122";
			function = "i2s0_sck";
			drive-strength = <8>;
			bias-disable;
		};

		data0-pins {
			pins = "gpio123";
			function = "i2s0_data0";
			drive-strength = <8>;
			bias-disable;
		};

		data1-pins {
			pins = "gpio124";
			function = "i2s0_data1";
			drive-strength = <8>;
			bias-disable;
		};

		ws-pins {
			pins = "gpio125";
			function = "i2s0_ws";
			drive-strength = <8>;
			bias-disable;
		};
	};

	speaker_top_default: speaker-top-default-state {
		reset-pins {
			pins = "gpio54";
			function = "gpio";
			drive-strength = <16>;
			bias-disable;
		};

		irq-pins {
			pins = "gpio47";
			function = "gpio";
			drive-strength = <2>;
			bias-pull-up;
		};

		/* The top amplifier's receiver switch, low for the speaker as on stock */
		rcv-pins {
			pins = "gpio174";
			function = "gpio";
			drive-strength = <2>;
			bias-disable;
			output-low;
		};
	};

	sw_ctrl_default: sw-ctrl-default-state {
		pins = "gpio18";
		function = "gpio";
		bias-pull-down;
	};

	ts_avdd_en: ts-avdd-en-state {
		pins = "gpio117";
		function = "gpio";
		bias-disable;
	};

	ts_default: ts-default-state {
		pins = "gpio66", "gpio158";
		function = "gpio";
		bias-disable;
	};

	usb_dp_qmpphy_portselect: usb-dp-qmpphy-portselect-state {
		pins = "gpio60";
		function = "usb_phy";
		drive-strength = <2>;
		bias-pull-down;
	};

	wlan_en: wlan-en-state {
		pins = "gpio16";
		function = "gpio";
		drive-strength = <8>;
		bias-pull-down;
	};
};

&uart18 {
	status = "okay";

	/* The combo's Bluetooth half, on stock's high-speed UART (SE18) */
	bluetooth {
		compatible = "qcom,wcn7860-bt";

		/*
		 * Xiaomi's Brahma patch and board 0x3e's RF settings, from the
		 * stock bluetooth partition. The controller reports board 0, and
		 * the generic brhbtnv20.bin leaves its receiver some 50 dB deaf.
		 */
		firmware-name = "brhbtnv20.b3e", "brhbtfw20.tlv";

		vddrfacmn-supply = <&vreg_pmu_rfa_cmn>;
		vddaon-supply = <&vreg_pmu_aon_0p59>;
		vddwlcx-supply = <&vreg_pmu_wlcx_0p8>;
		vddwlmx-supply = <&vreg_pmu_wlmx_0p85>;
		vddrfa0p8-supply = <&vreg_pmu_rfa_0p8>;
		vddrfa1p2-supply = <&vreg_pmu_rfa_1p2>;
		vddrfa1p8-supply = <&vreg_pmu_rfa_1p8>;

		max-speed = <3200000>;
	};
};

&ufs_mem_hc {
	reset-gpios = <&tlmm 217 GPIO_ACTIVE_LOW>;

	vcc-supply = <&vreg_l17b_2p5>;
	vcc-max-microamp = <1200000>;
	vccq-supply = <&vreg_l4d_1p2>;
	vccq-max-microamp = <1200000>;

	status = "okay";
};

&ufs_mem_phy {
	vdda-phy-supply = <&vreg_l4g_0p9>;
	vdda-pll-supply = <&vreg_l1d_1p2>;

	status = "okay";
};

&usb {
	/*
	 * The data role comes from pmic-glink (UCSI) on the SoCCP. Start as a
	 * device, so the USB network shell is up before the role is known.
	 */
	dr_mode = "otg";
	usb-role-switch;
	role-switch-default-mode = "peripheral";

	status = "okay";
};

&usb_hsphy {
	vdd-supply = <&vreg_l4f_0p8>;
	vdda12-supply = <&vreg_l1d_1p2>;

	phys = <&pmih0108_e1_eusb2_repeater>;

	status = "okay";
};

&usb_dp_qmpphy {
	vdda-phy-supply = <&vreg_l4f_0p8>;
	vdda-pll-supply = <&vreg_l1d_1p2>;

	pinctrl-0 = <&usb_dp_qmpphy_portselect>;
	pinctrl-names = "default";

	status = "okay";
};

&usb_dp_qmpphy_out {
	remote-endpoint = <&pmic_glink_ss_in>;
};

&usb_dwc3_hs {
	remote-endpoint = <&pmic_glink_hs_in>;
};
